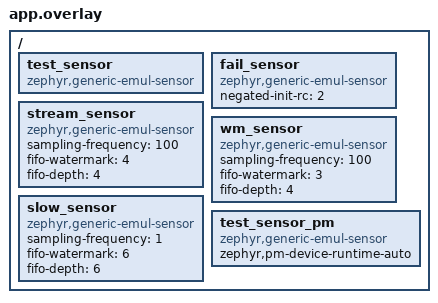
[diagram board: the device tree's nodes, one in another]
/*
 * Copyright (c) 2026 Embeint Inc
 *
 * SPDX-License-Identifier: Apache-2.0
 */

/ {
	test_sensor: test_sensor {
		compatible = "zephyr,generic-emul-sensor";
		status = "okay";
	};

	fail_sensor: fail_sensor {
		compatible = "zephyr,generic-emul-sensor";
		negated-init-rc = <2>;
		status = "okay";
	};

	stream_sensor: stream_sensor {
		compatible = "zephyr,generic-emul-sensor";
		sampling-frequency = <100>;
		fifo-watermark = <4>;
		fifo-depth = <4>;
		status = "okay";
	};

	wm_sensor: wm_sensor {
		compatible = "zephyr,generic-emul-sensor";
		sampling-frequency = <100>;
		fifo-watermark = <3>;
		fifo-depth = <4>;
		status = "okay";
	};

	slow_sensor: slow_sensor {
		compatible = "zephyr,generic-emul-sensor";
		sampling-frequency = <1>;
		fifo-watermark = <6>;
		fifo-depth = <6>;
		status = "okay";
	};

	test_sensor_pm: test_sensor_pm {
		compatible = "zephyr,generic-emul-sensor";
		zephyr,pm-device-runtime-auto;
		status = "okay";
	};
};
